# STM32L15x register map
File version: 1.0
Registers are 32-bit, read-write, reset 0x0 unless marked. A register's access mark holds for its fields unless they carry their own. Offsets are from the block's base; [hi:lo] are bit positions; {n}, {i} and the like mark numbered series.

## TIM11 — General-purpose timers
Base 0x40011000
Same registers: TIM2 0x40000000, TIM3 0x40000400, TIM4 0x40000800, TIM6 0x40001000, TIM7 0x40001400, TIM9 0x40010800, TIM10 0x40010C00
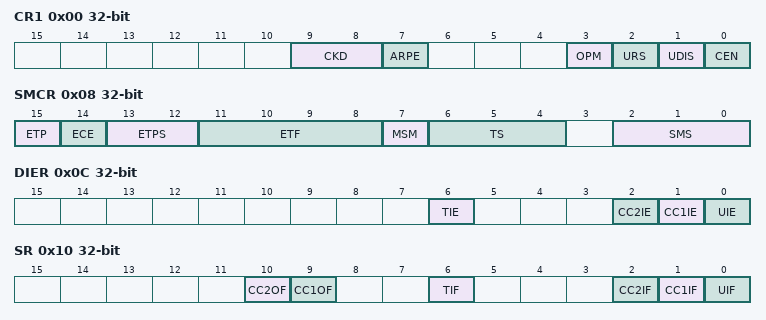
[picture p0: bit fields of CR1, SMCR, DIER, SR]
0x00 CR1 — TIMx control register 1
  [9:8] CKD, [7] ARPE, [3] OPM, [2] URS, [1] UDIS, [0] CEN
0x04 CR2 ro — TIMx control register 2
  [6:4] MMS
0x08 SMCR — TIMx slave mode control register
  [15] ETP, [14] ECE, [13:12] ETPS, [11:8] ETF, [7] MSM, [6:4] TS, [2:0] SMS
0x0C DIER — TIMx Interrupt enable register
  [6] TIE, [2] CC2IE, [1] CC1IE, [0] UIE
0x10 SR ro — TIMx status register
  [10] CC2OF, [9] CC1OF, [6] TIF, [2] CC2IF, [1] CC1IF, [0] UIF
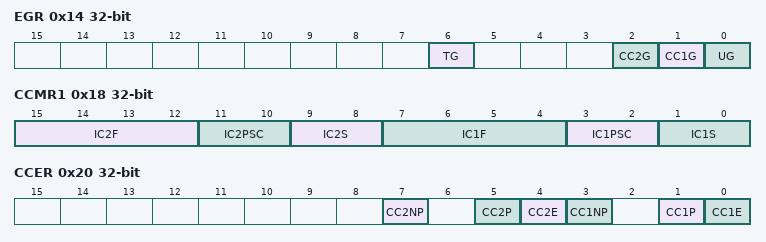
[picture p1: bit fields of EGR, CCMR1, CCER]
0x14 EGR wo — TIMx event generation register
  [6] TG, [2] CC2G, [1] CC1G, [0] UG
0x18 CCMR1 — TIMx capture/compare mode register 1
  [15:12] IC2F, [11:10] IC2PSC, [9:8] IC2S, [7:4] IC1F, [3:2] IC1PSC, [1:0] IC1S
0x20 CCER — TIMx capture/compare enable register
  [7] CC2NP, [5] CC2P, [4] CC2E, [3] CC1NP, [1] CC1P, [0] CC1E
0x24 CNT — TIMx counter
  [15:0] CNT
0x28 PSC — TIMx prescaler
  [15:0] PSC
0x2C ARR — TIMx auto-reload register
  [15:0] ARR
0x34 CCR1 — TIMx capture/compare register 1
  [15:0] CCR1
0x38 CCR2 — TIMx capture/compare register 2
  [15:0] CCR2
0x50 OR — option register
  [1:0] TI1_RMP

## SYSCFG — System configuration controller
Base 0x40010000
0x00 MEMRMP — SYSCFG memory remap register
  [1:0] MEM_MODE
0x04 PMC — SYSCFG peripheral mode configuration register
  [0] DP_USB_PU_EN
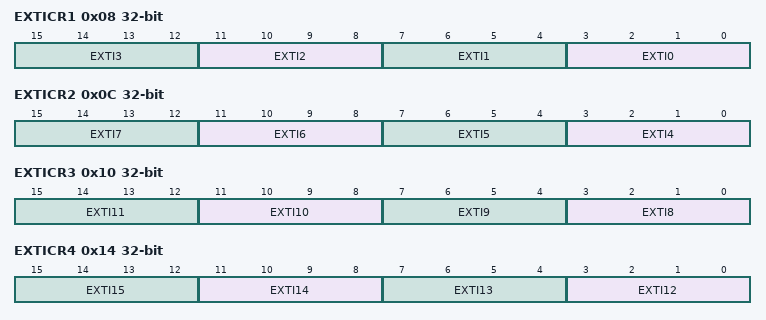
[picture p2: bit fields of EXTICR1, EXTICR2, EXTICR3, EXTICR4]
0x08 EXTICR1 — SYSCFG external interrupt configuration register 1
  [4n+3:4n] EXTI{n} (n=0..3)
0x0C EXTICR2 — SYSCFG external interrupt configuration register 2
  [4n-13:4n-16] EXTI{n} (n=4..7)
0x10 EXTICR3 — SYSCFG external interrupt configuration register 3
  [4n-29:4n-32] EXTI{n} (n=8..11)
0x14 EXTICR4 — SYSCFG external interrupt configuration register 4
  [4n-45:4n-48] EXTI{n} (n=12..15)

## COMP — Comparators
Base 0x40007C00
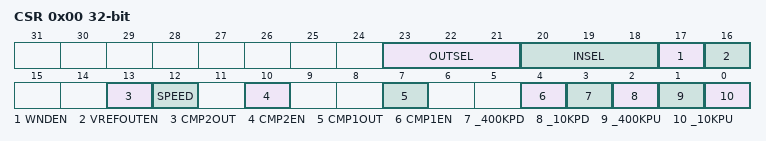
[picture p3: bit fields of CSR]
0x00 CSR — COMP comparator control and status register
  [23:21] OUTSEL, [20:18] INSEL, [17] WNDEN, [16] VREFOUTEN, [13] CMP2OUT, [12] SPEED, [10] CMP2EN, [7] CMP1OUT, [4] CMP1EN, [3] _400KPD, [2] _10KPD, [1] _400KPU, [0] _10KPU

## DAC — Digital-to-analog converter
Base 0x40007400
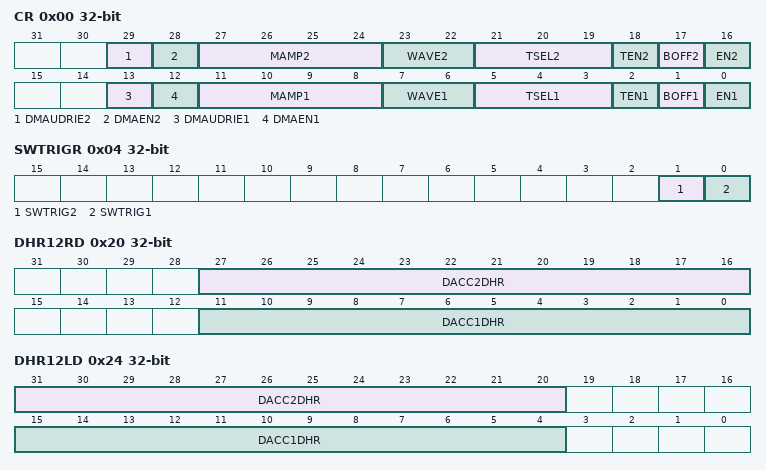
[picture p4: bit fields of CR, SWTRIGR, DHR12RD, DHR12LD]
0x00 CR — DAC control register
  [29] DMAUDRIE2, [28] DMAEN2, [27:24] MAMP2, [23:22] WAVE2, [21:19] TSEL2, [18] TEN2, [17] BOFF2, [16] EN2, [13] DMAUDRIE1, [12] DMAEN1, [11:8] MAMP1, [7:6] WAVE1, [5:3] TSEL1, [2] TEN1, [1] BOFF1, [0] EN1
0x04 SWTRIGR wo — DAC software trigger register
  [1] SWTRIG2, [0] SWTRIG1
0x08 DHR12R1 — DAC channel1 12-bit right-aligned data holding register
  [11:0] DACC1DHR
0x0C DHR12L1 — DAC channel1 12-bit left aligned data holding register
  [15:4] DACC1DHR
0x10 DHR8R1 — DAC channel1 8-bit right aligned data holding register
  [7:0] DACC1DHR
0x14 DHR12R2 — DAC channel2 12-bit right aligned data holding register
  [11:0] DACC2DHR
0x18 DHR12L2 — DAC channel2 12-bit left aligned data holding register
  [15:4] DACC2DHR
0x1C DHR8R2 — DAC channel2 8-bit right-aligned data holding register
  [7:0] DACC2DHR
0x20 DHR12RD — Dual DAC 12-bit right-aligned data holding register
  [27:16] DACC2DHR, [11:0] DACC1DHR
0x24 DHR12LD — DUAL DAC 12-bit left aligned data holding register
  [31:20] DACC2DHR, [15:4] DACC1DHR
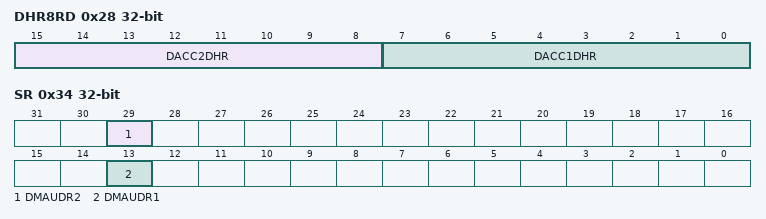
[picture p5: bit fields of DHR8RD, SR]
0x28 DHR8RD — DUAL DAC 8-bit right aligned data holding register
  [15:8] DACC2DHR, [7:0] DACC1DHR
0x2C DOR1 ro — DAC channel1 data output register
  [11:0] DACC1DOR
0x30 DOR2 ro — DAC channel2 data output register
  [11:0] DACC2DOR
0x34 SR wo — DAC status register
  [29] DMAUDR2, [13] DMAUDR1

## PWR — Power control
Base 0x40007000
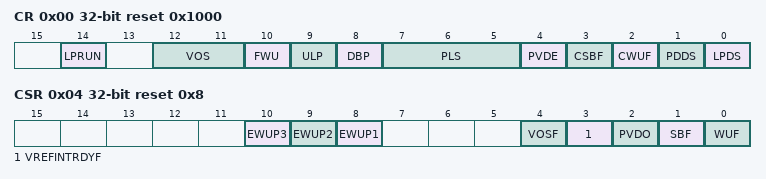
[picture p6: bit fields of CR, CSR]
0x00 CR access per field reset 0x1000 — PWR power control register
  [14] LPRUN rw, [12:11] VOS rw, [10] FWU rw, [9] ULP rw, [8] DBP rw, [7:5] PLS rw, [4] PVDE rw, [3] CSBF wo, [2] CWUF wo, [1] PDDS rw, [0] LPDS rw
0x04 CSR access per field reset 0x8 — PWR power control/status register
  [10] EWUP3 rw, [9] EWUP2 rw, [8] EWUP1 rw, [4] VOSF ro, [3] VREFINTRDYF ro, [2] PVDO ro, [1] SBF ro, [0] WUF ro
